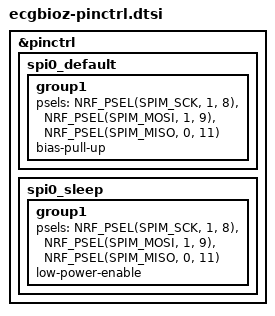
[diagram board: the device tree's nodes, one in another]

&pinctrl {
    spi0_default: spi0_default {
        group1 {
            psels = <NRF_PSEL(SPIM_SCK, 1, 8)>,
                <NRF_PSEL(SPIM_MOSI, 1, 9)>,
                <NRF_PSEL(SPIM_MISO, 0, 11)>;
            bias-pull-up;   /* 关键：给 MISO 上拉 */
        };
	};

	spi0_sleep: spi0_sleep {
		group1 {
			psels = <NRF_PSEL(SPIM_SCK, 1, 8)>,
				<NRF_PSEL(SPIM_MOSI, 1, 9)>,
				<NRF_PSEL(SPIM_MISO, 0, 11)>;
			low-power-enable;
		};
	};
};



